# BAT32A239 register map
Vendor: CMS; Series: BAT32A239; File version: 1.0
CPU: CM0+ r0p1, little endian, MPU, no FPU, VTOR, 2 interrupt priority bits
Registers are 8-bit, read-write, reset 0x0 unless marked. A register's access mark holds for its fields unless they carry their own. Offsets are from the block's base; [hi:lo] are bit positions; {n}, {i} and the like mark numbered series.

## IICA0 — Serial Interface I2C with multimaster and wakeup supported
Base 0x40041A30
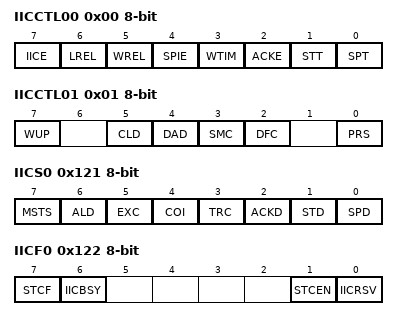
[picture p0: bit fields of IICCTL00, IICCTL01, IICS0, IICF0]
0x00 IICCTL00 — IICA control register 0
  [7] IICE — I2C operation enable
  [6] LREL — Exit from communications
  [5] WREL — Wait cancellation
  [4] SPIE — Enable generation of interrupt request when stop condition is detected
  [3] WTIM — Control of wait and interrupt request generation
  [2] ACKE — Acknowledgment control
  [1] STT — Start condition trigger
  [0] SPT — Stop condition trigger
0x01 IICCTL01 — IICA control register 1
  [7] WUP — Control of address match wakeup
  [5] CLD ro — Detection of SCLAn pin level (valid only when IICEn = 1)
  [4] DAD ro — Detection of SDAAn pin level (valid only when IICEn = 1)
  [3] SMC — Operation mode switching
  [2] DFC — Digital filter operation control
  [0] PRS — Operation clock (fMCK) contro
0x02 IICWL0 reset 0xFF — IICA low-level width setting register 0
0x03 IICWH0 reset 0xFF — IICA high-level width setting register 0
0x04 SVA0 (reset mask 0xFE) — Slave address register 0
0x120 IICA00 — IICA shift register 00
0x121 IICS0 ro — IICA status register 0
  [7] MSTS — Master status check flag
  [6] ALD — Detection of arbitration loss
  [5] EXC — Detection of extension code reception
  [4] COI — Detection of matching addresses
  [3] TRC — Detection of transmit/receive status
  [2] ACKD — Detection of acknowledge (ACK)
  [1] STD — Detection of start condition
  [0] SPD — Detection of stop condition
0x122 IICF0 — IICA flag register 0
  [7] STCF ro — STT clear flag
  [6] IICBSY ro — I2C bus status flag
  [1] STCEN — Initial start enable trigger
  [0] IICRSV — Communication reservation function disable bit

## IICA1 — Serial Interface I2C with multimaster and wakeup supported
Base 0x40046230
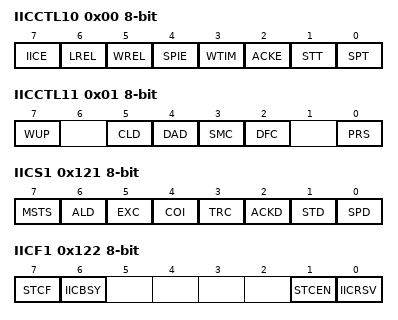
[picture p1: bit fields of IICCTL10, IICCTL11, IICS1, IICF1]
0x00 IICCTL10 — IICA control register 0
  [7] IICE — I2C operation enable
  [6] LREL — Exit from communications
  [5] WREL — Wait cancellation
  [4] SPIE — Enable generation of interrupt request when stop condition is detected
  [3] WTIM — Control of wait and interrupt request generation
  [2] ACKE — Acknowledgment control
  [1] STT — Start condition trigger
  [0] SPT — Stop condition trigger
0x01 IICCTL11 — IICA control register 1
  [7] WUP — Control of address match wakeup
  [5] CLD ro — Detection of SCLAn pin level (valid only when IICEn = 1)
  [4] DAD ro — Detection of SDAAn pin level (valid only when IICEn = 1)
  [3] SMC — Operation mode switching
  [2] DFC — Digital filter operation control
  [0] PRS — Operation clock (fMCK) contro
0x02 IICWL1 reset 0xFF — IICA low-level width setting register 1
0x03 IICWH1 reset 0xFF — IICA high-level width setting register 1
0x04 SVA1 (reset mask 0xFE) — Slave address register 1
0x120 IICA10 — IICA shift register 10
0x121 IICS1 ro — IICA status register 1
  [7] MSTS — Master status check flag
  [6] ALD — Detection of arbitration loss
  [5] EXC — Detection of extension code reception
  [4] COI — Detection of matching addresses
  [3] TRC — Detection of transmit/receive status
  [2] ACKD — Detection of acknowledge (ACK)
  [1] STD — Detection of start condition
  [0] SPD — Detection of stop condition
0x122 IICF1 — IICA flag register 1
  [7] STCF ro — STT clear flag
  [6] IICBSY ro — I2C bus status flag
  [1] STCEN — Initial start enable trigger
  [0] IICRSV — Communication reservation function disable bit

## DMA — Enhanced DMA Controller
Base 0x40005000
{0x0+i} DMAEN{i} (i=0..4) — DMA activation enable register {i}
0x08 DMABAR 32-bit — DMA base address register
0x0C IFPRCR 32-bit — DMA Trigger Protect register
{0x10+i} DMAIF{i} (i=0..4) — DMA Trigger enable register {i}
{0x18+i} DMSET{i} (i=0..4) — DMA activation enable set register {i}
{0x20+i} DMCLR{i} (i=0..4) — DMA activation enable clear register {i}
